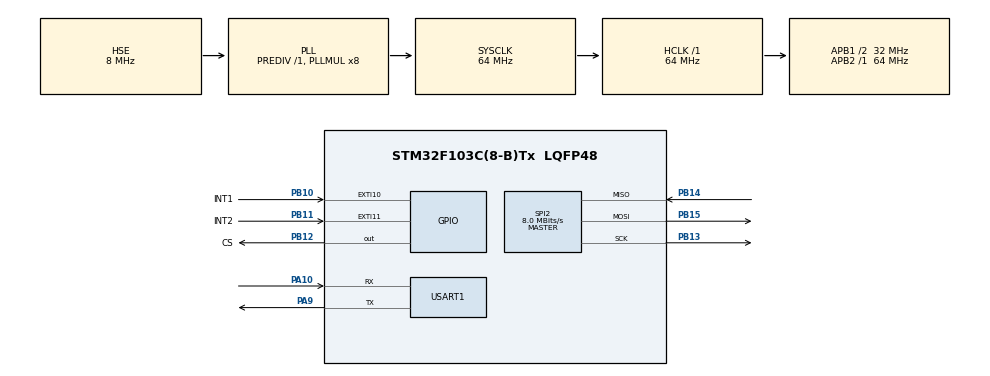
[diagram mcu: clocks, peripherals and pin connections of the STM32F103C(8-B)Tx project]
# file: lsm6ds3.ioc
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Mcu.Family=STM32F1
Mcu.Name=STM32F103C(8-B)Tx
Mcu.Package=LQFP48
NVIC.EXTI15_10_IRQn=true\:0\:0\:false\:false\:true\:true\:true\:true
NVIC.PriorityGroup=NVIC_PRIORITYGROUP_4
PA10.Mode=Asynchronous
PA10.Signal=USART1_RX
PA9.Mode=Asynchronous
PA9.Signal=USART1_TX
PB10.GPIO_Label=INT1
PB10.Signal=GPXTI10
PB11.GPIO_Label=INT2
PB11.Signal=GPXTI11
PB12.GPIO_Label=CS
PB12.Signal=GPIO_Output
PB13.Mode=Full_Duplex_Master
PB13.Signal=SPI2_SCK
PB14.Mode=Full_Duplex_Master
PB14.Signal=SPI2_MISO
PB15.Mode=Full_Duplex_Master
PB15.Signal=SPI2_MOSI
PD0-OSC_IN.Mode=HSE-External-Oscillator
PD0-OSC_IN.Signal=RCC_OSC_IN
PD1-OSC_OUT.Mode=HSE-External-Oscillator
PD1-OSC_OUT.Signal=RCC_OSC_OUT
ProjectManager.HeapSize=0x200
ProjectManager.StackSize=0x400
ProjectManager.TargetToolchain=STM32CubeIDE
RCC.AHBFreq_Value=64000000
RCC.APB1CLKDivider=RCC_HCLK_DIV2
RCC.APB1Freq_Value=32000000
RCC.APB1TimFreq_Value=64000000
RCC.APB2Freq_Value=64000000
RCC.APB2TimFreq_Value=64000000
RCC.HCLKFreq_Value=64000000
RCC.PLLMUL=RCC_PLL_MUL8
RCC.PLLSourceVirtual=RCC_PLLSOURCE_HSE
RCC.SYSCLKFreq_VALUE=64000000
RCC.SYSCLKSource=RCC_SYSCLKSOURCE_PLLCLK
RCC.USBFreq_Value=64000000
SPI2.BaudRatePrescaler=SPI_BAUDRATEPRESCALER_4
SPI2.CalculateBaudRate=8.0 MBits/s
SPI2.Direction=SPI_DIRECTION_2LINES
SPI2.Mode=SPI_MODE_MASTER
SPI2.VirtualType=VM_MASTER
USART1.VirtualMode=VM_ASYNC
VP_SYS_VS_ND.Mode=No_Debug
board=custom

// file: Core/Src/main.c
/* USER CODE BEGIN Header */
/**
  ******************************************************************************
  * @file           : main.c
  * @brief          : Main program body
  ******************************************************************************
  * @attention
  *
  * Copyright (c) 2024 STMicroelectronics.
  * All rights reserved.
  *
  * This software is licensed under terms that can be found in the LICENSE file
  * in the root directory of this software component.
  * If no LICENSE file comes with this software, it is provided AS-IS.
  *
  ******************************************************************************
  */
/* USER CODE END Header */
#include "main.h"

/* USER CODE BEGIN Includes */
#include <stdio.h>
#include <string.h>
#include "lsm6ds3.h"
#include "lsm6ds3_reg.h"

/* USER CODE END Includes */

SPI_HandleTypeDef hspi2;

UART_HandleTypeDef huart1;

void SystemClock_Config(void);
static void MX_GPIO_Init(void);
static void MX_SPI2_Init(void);
static void MX_USART1_UART_Init(void);

int main(void)
{

  /* MCU Configuration--------------------------------------------------------*/

  /* Reset of all peripherals, Initializes the Flash interface and the Systick. */
  HAL_Init();

  /* Configure the system clock */
  SystemClock_Config();

  /* Initialize all configured peripherals */
  MX_GPIO_Init();
  MX_SPI2_Init();
  MX_USART1_UART_Init();
  /* USER CODE BEGIN 2 */

  //look at lsm6ds3_reg.h:999 for value meaning
  lsm6ds3_settings_t lsm6ds_settings = {
      .lsm6ds3_xl_fs = LSM6DS3_16g,
      .lsm6ds3_fs_g = LSM6DS3_2000dps,
      .lsm6ds3_odr_xl = LSM6DS3_XL_ODR_6k66Hz,
      .lsm6ds3_odr_g = LSM6DS3_GY_ODR_1k66Hz
  };

  uint8_t whoami = lsm6ds3_init(lsm6ds_settings, hspi2);

  /*float* xl_data;
  float* g_data;*/

  /* USER CODE END 2 */

  /* Infinite loop */
  while (1)
  {

    /* USER CODE BEGIN 3 */

	  HAL_UART_Transmit(&huart1, whoami, strlen(whoami), 10);

	  /*lsm6ds3_update_data_interrupt();
	  xl_data = lsm6ds3_get_acc_data_mg();
	  g_data = lsm6ds3_get_gyro_data_mdps();

	  char tmp[40];
	  sprintf(tmp, "g: %.3f, %.3f, %.3f\r\n", g_data[0], g_data[1], g_data[2]);
	  HAL_UART_Transmit(&huart1, tmp, strlen(tmp), 10);
	  sprintf(tmp, "xl: %.3f, %.3f, %.3f\r\n", xl_data[0], xl_data[1], xl_data[2]);
	  HAL_UART_Transmit(&huart1, tmp, strlen(tmp), 10);*/
	  HAL_Delay(500);
  }
  /* USER CODE END 3 */
}

void SystemClock_Config(void)
{
  RCC_OscInitTypeDef RCC_OscInitStruct = {0};
  RCC_ClkInitTypeDef RCC_ClkInitStruct = {0};

  /** Initializes the RCC Oscillators according to the specified parameters
  * in the RCC_OscInitTypeDef structure.
  */
  RCC_OscInitStruct.OscillatorType = RCC_OSCILLATORTYPE_HSE;
  RCC_OscInitStruct.HSEState = RCC_HSE_ON;
  RCC_OscInitStruct.HSEPredivValue = RCC_HSE_PREDIV_DIV1;
  RCC_OscInitStruct.HSIState = RCC_HSI_ON;
  RCC_OscInitStruct.PLL.PLLState = RCC_PLL_ON;
  RCC_OscInitStruct.PLL.PLLSource = RCC_PLLSOURCE_HSE;
  RCC_OscInitStruct.PLL.PLLMUL = RCC_PLL_MUL8;
  if (HAL_RCC_OscConfig(&RCC_OscInitStruct) != HAL_OK)
  {
    Error_Handler();
  }

  /** Initializes the CPU, AHB and APB buses clocks
  */
  RCC_ClkInitStruct.ClockType = RCC_CLOCKTYPE_HCLK|RCC_CLOCKTYPE_SYSCLK
                              |RCC_CLOCKTYPE_PCLK1|RCC_CLOCKTYPE_PCLK2;
  RCC_ClkInitStruct.SYSCLKSource = RCC_SYSCLKSOURCE_PLLCLK;
  RCC_ClkInitStruct.AHBCLKDivider = RCC_SYSCLK_DIV1;
  RCC_ClkInitStruct.APB1CLKDivider = RCC_HCLK_DIV2;
  RCC_ClkInitStruct.APB2CLKDivider = RCC_HCLK_DIV1;

  if (HAL_RCC_ClockConfig(&RCC_ClkInitStruct, FLASH_LATENCY_2) != HAL_OK)
  {
    Error_Handler();
  }
}

static void MX_SPI2_Init(void)
{

  /* SPI2 parameter configuration*/
  hspi2.Instance = SPI2;
  hspi2.Init.Mode = SPI_MODE_MASTER;
  hspi2.Init.Direction = SPI_DIRECTION_2LINES;
  hspi2.Init.DataSize = SPI_DATASIZE_8BIT;
  hspi2.Init.CLKPolarity = SPI_POLARITY_LOW;
  hspi2.Init.CLKPhase = SPI_PHASE_1EDGE;
  hspi2.Init.NSS = SPI_NSS_SOFT;
  hspi2.Init.BaudRatePrescaler = SPI_BAUDRATEPRESCALER_4;
  hspi2.Init.FirstBit = SPI_FIRSTBIT_MSB;
  hspi2.Init.TIMode = SPI_TIMODE_DISABLE;
  hspi2.Init.CRCCalculation = SPI_CRCCALCULATION_DISABLE;
  hspi2.Init.CRCPolynomial = 10;
  if (HAL_SPI_Init(&hspi2) != HAL_OK)
  {
    Error_Handler();
  }

}

static void MX_USART1_UART_Init(void)
{

  huart1.Instance = USART1;
  huart1.Init.BaudRate = 115200;
  huart1.Init.WordLength = UART_WORDLENGTH_8B;
  huart1.Init.StopBits = UART_STOPBITS_1;
  huart1.Init.Parity = UART_PARITY_NONE;
  huart1.Init.Mode = UART_MODE_TX_RX;
  huart1.Init.HwFlowCtl = UART_HWCONTROL_NONE;
  huart1.Init.OverSampling = UART_OVERSAMPLING_16;
  if (HAL_UART_Init(&huart1) != HAL_OK)
  {
    Error_Handler();
  }

}

static void MX_GPIO_Init(void)
{
  GPIO_InitTypeDef GPIO_InitStruct = {0};

  /* GPIO Ports Clock Enable */
  __HAL_RCC_GPIOD_CLK_ENABLE();
  __HAL_RCC_GPIOB_CLK_ENABLE();
  __HAL_RCC_GPIOA_CLK_ENABLE();

  /*Configure GPIO pin Output Level */
  HAL_GPIO_WritePin(CS_GPIO_Port, CS_Pin, GPIO_PIN_RESET);

  /*Configure GPIO pins : INT1_Pin INT2_Pin */
  GPIO_InitStruct.Pin = INT1_Pin|INT2_Pin;
  GPIO_InitStruct.Mode = GPIO_MODE_IT_RISING;
  GPIO_InitStruct.Pull = GPIO_NOPULL;
  HAL_GPIO_Init(GPIOB, &GPIO_InitStruct);

  /*Configure GPIO pin : CS_Pin */
  GPIO_InitStruct.Pin = CS_Pin;
  GPIO_InitStruct.Mode = GPIO_MODE_OUTPUT_PP;
  GPIO_InitStruct.Pull = GPIO_NOPULL;
  GPIO_InitStruct.Speed = GPIO_SPEED_FREQ_LOW;
  HAL_GPIO_Init(CS_GPIO_Port, &GPIO_InitStruct);

  /* EXTI interrupt init*/
  HAL_NVIC_SetPriority(EXTI15_10_IRQn, 0, 0);
  HAL_NVIC_EnableIRQ(EXTI15_10_IRQn);

}

void Error_Handler(void)
{
  __disable_irq();
  while (1)
  {
  }
}
